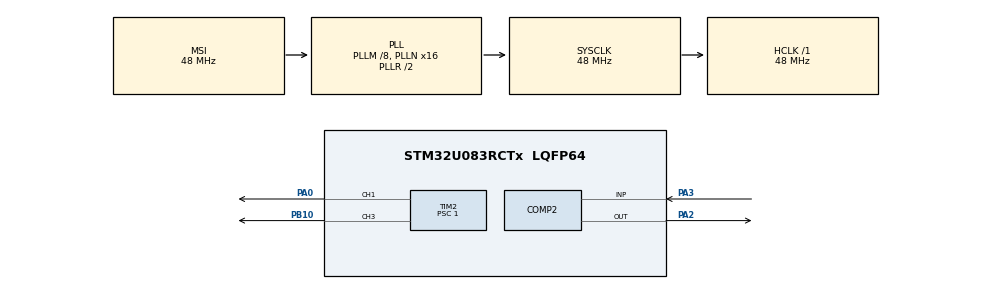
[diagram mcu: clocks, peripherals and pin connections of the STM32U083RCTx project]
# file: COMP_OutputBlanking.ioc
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COMP2.BlankingSrce=COMP_BLANKINGSRC_TIM2_OC3
COMP2.Hysteresis=COMP_HYSTERESIS_NONE
COMP2.Mode=COMP_POWERMODE_HIGHSPEED
COMP2.OutputPol=COMP_OUTPUTPOL_NONINVERTED
COMP2.TriggerMode=COMP_TRIGGERMODE_NONE
Mcu.Family=STM32U0
Mcu.Name=STM32U083RCTx
Mcu.Package=LQFP64
NVIC.PriorityGroup=NVIC_PRIORITYGROUP_2
PA0.Signal=S_TIM2_CH1_ETR
PA2.Mode=ExternalOutput
PA2.Signal=COMP2_OUT
PA3.Mode=INP
PA3.Signal=COMP2_INP
PB10.Signal=S_TIM2_CH3
ProjectManager.HeapSize=0x200
ProjectManager.StackSize=0x400
ProjectManager.TargetToolchain=EWARM V9.20
RCC.ADCFreq_Value=48000000
RCC.AHBFreq_Value=48000000
RCC.CortexFreq_Value=48000000
RCC.HCLKFreq_Value=48000000
RCC.HSE_VALUE=4000000
RCC.HSI48_VALUE=48000000
RCC.HSI_VALUE=16000000
RCC.LSE_VALUE=32768
RCC.MSIClockRangeVal=RCC_MSIRANGE_11
RCC.MSI_VALUE=48000000
RCC.PLLM=RCC_PLLM_DIV8
RCC.PLLN=16
RCC.PLLSourceVirtual=RCC_PLLSOURCE_MSI
RCC.SYSCLKFreq_VALUE=48000000
RCC.SYSCLKSource=RCC_SYSCLKSOURCE_PLLCLK
RCC.USBFreq_Value=48000000
RCC.VCOOutputFreq_Value=96000000
SH.S_TIM2_CH1_ETR.0=TIM2_CH1,PWM Generation1 CH1
SH.S_TIM2_CH3.0=TIM2_CH3,PWM Generation3 CH3
TIM2.AutoReloadPreload=TIM_AUTORELOAD_PRELOAD_DISABLE
TIM2.Channel-PWM\ Generation1\ CH1=TIM_CHANNEL_1
TIM2.Channel-PWM\ Generation3\ CH3=TIM_CHANNEL_3
TIM2.ClearInputSource=TIM_CLEARINPUTSOURCE_NONE
TIM2.ClockDivision=TIM_CLOCKDIVISION_DIV1
TIM2.CounterMode=TIM_COUNTERMODE_UP
TIM2.OC1Preload_PWM=ENABLE
TIM2.OC3Preload_PWM=ENABLE
TIM2.OCFastMode_PWM-PWM\ Generation1\ CH1=TIM_OCFAST_DISABLE
TIM2.OCFastMode_PWM-PWM\ Generation3\ CH3=TIM_OCFAST_DISABLE
TIM2.OCMode_PWM-PWM\ Generation1\ CH1=TIM_OCMODE_PWM1
TIM2.OCMode_PWM-PWM\ Generation3\ CH3=TIM_OCMODE_PWM1
TIM2.OCPolarity_1=TIM_OCPOLARITY_HIGH
TIM2.OCPolarity_3=TIM_OCPOLARITY_HIGH
TIM2.Period=79999
TIM2.PeriodNoDither=79999
TIM2.Prescaler=1
TIM2.PulseNoDither_1=4350
TIM2.PulseNoDither_3=1000
TIM2.TIM_MasterOutputTrigger=TIM_TRGO_RESET
TIM2.TIM_MasterSlaveMode=TIM_MASTERSLAVEMODE_DISABLE
VP_COMP2_VS_VREFINT.Mode=VREFINT
VP_TIM2_VS_ClockSourceINT.Mode=Internal
board=custom

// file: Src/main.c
/* USER CODE BEGIN Header */
/**
  ******************************************************************************
  * @file    Examples/COMP/COMP_OutputBlanking/Src/main.c
  * @author  MCD Application Team
  * @brief   This example provides a short description of how to use the COMP
  *          peripheral in mode output blanking feature.
  ******************************************************************************
  * @attention
  *
  * Copyright (c) 2023 STMicroelectronics.
  * All rights reserved.
  *
  * This software is licensed under terms that can be found in the LICENSE file
  * in the root directory of this software component.
  * If no LICENSE file comes with this software, it is provided AS-IS.
  *
  ******************************************************************************
  */
/* USER CODE END Header */
#include "main.h"

/* USER CODE BEGIN Includes */
#include "stm32u0xx_nucleo.h"
/* USER CODE END Includes */

COMP_HandleTypeDef hcomp2;

TIM_HandleTypeDef htim2;

/* USER CODE BEGIN PV */
__IO uint32_t State = 0;
/* USER CODE END PV */

void SystemClock_Config(void);
static void MX_GPIO_Init(void);
static void MX_TIM2_Init(void);
static void MX_COMP2_Init(void);

int main(void)
{

  /* MCU Configuration--------------------------------------------------------*/

  /* Reset of all peripherals, Initializes the Flash interface and the Systick. */
  HAL_Init();

  /* Configure the system clock */
  SystemClock_Config();

  /* USER CODE BEGIN SysInit */
  /******* Initialize LEDs available on NUCLEO-U083RC board ******************/
  BSP_LED_Init(LED4);
  /* USER CODE END SysInit */

  /* Initialize all configured peripherals */
  MX_GPIO_Init();
  MX_TIM2_Init();
  MX_COMP2_Init();
  /* USER CODE BEGIN 2 */

  BSP_LED_Init(LED4);
  BSP_LED_Off(LED4);

 /*##-1- Start the comparator COMP2 #####################################*/
  if (HAL_COMP_Start(&hcomp2) != HAL_OK)
  {
    /* Initialization Error */
    Error_Handler();
  }

 /*##-2- Enable TIM peripheral counter ######################################*/
  /* Start the TIM2 Channel TIM_CHANNEL_1 PWM */
  if(HAL_TIM_PWM_Start(&htim2, TIM_CHANNEL_1) != HAL_OK)
  {
    Error_Handler();
  }

  /* Start the TIM2 Channel TIM_CHANNEL_3 PWM */
  if(HAL_TIM_PWM_Start(&htim2, TIM_CHANNEL_3) != HAL_OK)
  {
    Error_Handler();
  }
  /* USER CODE END 2 */

  /* Infinite loop */
  while (1)
  {

    /* USER CODE BEGIN 3 */
    /* Toggle LED4 as heart beat */
    BSP_LED_Toggle(LED4);
    HAL_Delay(500);
  }
  /* USER CODE END 3 */
}

void SystemClock_Config(void)
{
  RCC_OscInitTypeDef RCC_OscInitStruct = {0};
  RCC_ClkInitTypeDef RCC_ClkInitStruct = {0};

  /** Configure the main internal regulator output voltage
  */
  HAL_PWREx_ControlVoltageScaling(PWR_REGULATOR_VOLTAGE_SCALE1);

  /** Initializes the RCC Oscillators according to the specified parameters
  * in the RCC_OscInitTypeDef structure.
  */
  RCC_OscInitStruct.OscillatorType = RCC_OSCILLATORTYPE_MSI;
  RCC_OscInitStruct.MSIState = RCC_MSI_ON;
  RCC_OscInitStruct.MSICalibrationValue = RCC_MSICALIBRATION_DEFAULT;
  RCC_OscInitStruct.MSIClockRange = RCC_MSIRANGE_11;
  RCC_OscInitStruct.PLL.PLLState = RCC_PLL_ON;
  RCC_OscInitStruct.PLL.PLLSource = RCC_PLLSOURCE_MSI;
  RCC_OscInitStruct.PLL.PLLM = RCC_PLLM_DIV8;
  RCC_OscInitStruct.PLL.PLLN = 16;
  RCC_OscInitStruct.PLL.PLLP = RCC_PLLP_DIV2;
  RCC_OscInitStruct.PLL.PLLQ = RCC_PLLQ_DIV2;
  RCC_OscInitStruct.PLL.PLLR = RCC_PLLR_DIV2;
  if (HAL_RCC_OscConfig(&RCC_OscInitStruct) != HAL_OK)
  {
    Error_Handler();
  }

  /** Initializes the CPU, AHB and APB buses clocks
  */
  RCC_ClkInitStruct.ClockType = RCC_CLOCKTYPE_HCLK|RCC_CLOCKTYPE_SYSCLK
                              |RCC_CLOCKTYPE_PCLK1;
  RCC_ClkInitStruct.SYSCLKSource = RCC_SYSCLKSOURCE_PLLCLK;
  RCC_ClkInitStruct.AHBCLKDivider = RCC_SYSCLK_DIV1;
  RCC_ClkInitStruct.APB1CLKDivider = RCC_HCLK_DIV1;

  if (HAL_RCC_ClockConfig(&RCC_ClkInitStruct, FLASH_LATENCY_1) != HAL_OK)
  {
    Error_Handler();
  }
}

static void MX_COMP2_Init(void)
{

  hcomp2.Instance = COMP2;
  hcomp2.Init.InputPlus = COMP_INPUT_PLUS_IO3;
  hcomp2.Init.InputMinus = COMP_INPUT_MINUS_VREFINT;
  hcomp2.Init.OutputPol = COMP_OUTPUTPOL_NONINVERTED;
  hcomp2.Init.WindowOutput = COMP_WINDOWOUTPUT_EACH_COMP;
  hcomp2.Init.Hysteresis = COMP_HYSTERESIS_NONE;
  hcomp2.Init.BlankingSrce = COMP_BLANKINGSRC_TIM2_OC3;
  hcomp2.Init.Mode = COMP_POWERMODE_HIGHSPEED;
  hcomp2.Init.WindowMode = COMP_WINDOWMODE_DISABLE;
  hcomp2.Init.TriggerMode = COMP_TRIGGERMODE_NONE;
  if (HAL_COMP_Init(&hcomp2) != HAL_OK)
  {
    Error_Handler();
  }

}

static void MX_TIM2_Init(void)
{

  TIM_ClockConfigTypeDef sClockSourceConfig = {0};
  TIM_MasterConfigTypeDef sMasterConfig = {0};
  TIM_OC_InitTypeDef sConfigOC = {0};

  htim2.Instance = TIM2;
  htim2.Init.Prescaler = 1;
  htim2.Init.CounterMode = TIM_COUNTERMODE_UP;
  htim2.Init.Period = 79999;
  htim2.Init.ClockDivision = TIM_CLOCKDIVISION_DIV1;
  htim2.Init.AutoReloadPreload = TIM_AUTORELOAD_PRELOAD_DISABLE;
  if (HAL_TIM_Base_Init(&htim2) != HAL_OK)
  {
    Error_Handler();
  }
  sClockSourceConfig.ClockSource = TIM_CLOCKSOURCE_INTERNAL;
  if (HAL_TIM_ConfigClockSource(&htim2, &sClockSourceConfig) != HAL_OK)
  {
    Error_Handler();
  }
  if (HAL_TIM_PWM_Init(&htim2) != HAL_OK)
  {
    Error_Handler();
  }
  sMasterConfig.MasterOutputTrigger = TIM_TRGO_RESET;
  sMasterConfig.MasterSlaveMode = TIM_MASTERSLAVEMODE_DISABLE;
  if (HAL_TIMEx_MasterConfigSynchronization(&htim2, &sMasterConfig) != HAL_OK)
  {
    Error_Handler();
  }
  sConfigOC.OCMode = TIM_OCMODE_PWM1;
  sConfigOC.Pulse = 0;
  sConfigOC.OCPolarity = TIM_OCPOLARITY_HIGH;
  sConfigOC.OCFastMode = TIM_OCFAST_DISABLE;
  if (HAL_TIM_PWM_ConfigChannel(&htim2, &sConfigOC, TIM_CHANNEL_1) != HAL_OK)
  {
    Error_Handler();
  }
  if (HAL_TIM_PWM_ConfigChannel(&htim2, &sConfigOC, TIM_CHANNEL_3) != HAL_OK)
  {
    Error_Handler();
  }
  HAL_TIM_MspPostInit(&htim2);

}

static void MX_GPIO_Init(void)
{

  /* GPIO Ports Clock Enable */
  __HAL_RCC_GPIOA_CLK_ENABLE();
  __HAL_RCC_GPIOB_CLK_ENABLE();

}

void Error_Handler(void)
{
  /* USER CODE BEGIN Error_Handler_Debug */
  /* User can add his own implementation to report the HAL error return state */

  BSP_LED_On(LED4);
    while(1)
    {
    }

  /* USER CODE END Error_Handler_Debug */
}
